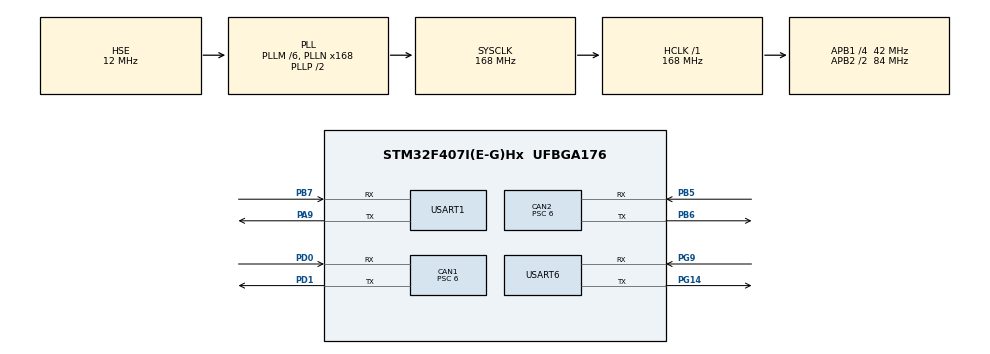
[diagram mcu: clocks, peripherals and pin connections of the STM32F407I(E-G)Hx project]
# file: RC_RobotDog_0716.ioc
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CAN1.BS1=CAN_BS1_3TQ
CAN1.BS2=CAN_BS2_3TQ
CAN1.CalculateBaudRate=1000000
CAN1.CalculateTimeBit=1000
CAN1.CalculateTimeQuantum=142.85714285714286
CAN1.NART=ENABLE
CAN1.Prescaler=6
CAN2.BS1=CAN_BS1_3TQ
CAN2.BS2=CAN_BS2_3TQ
CAN2.CalculateBaudRate=1000000
CAN2.CalculateTimeBit=1000
CAN2.CalculateTimeQuantum=142.85714285714286
CAN2.Prescaler=6
Dma.Request0=USART6_RX
Dma.Request1=USART1_RX
Dma.USART1_RX.1.Direction=DMA_PERIPH_TO_MEMORY
Dma.USART1_RX.1.FIFOMode=DMA_FIFOMODE_DISABLE
Dma.USART1_RX.1.Instance=DMA2_Stream2
Dma.USART1_RX.1.MemDataAlignment=DMA_MDATAALIGN_BYTE
Dma.USART1_RX.1.MemInc=DMA_MINC_ENABLE
Dma.USART1_RX.1.Mode=DMA_NORMAL
Dma.USART1_RX.1.PeriphDataAlignment=DMA_PDATAALIGN_BYTE
Dma.USART1_RX.1.PeriphInc=DMA_PINC_DISABLE
Dma.USART1_RX.1.Priority=DMA_PRIORITY_LOW
Dma.USART6_RX.0.Direction=DMA_PERIPH_TO_MEMORY
Dma.USART6_RX.0.FIFOMode=DMA_FIFOMODE_ENABLE
Dma.USART6_RX.0.FIFOThreshold=DMA_FIFO_THRESHOLD_FULL
Dma.USART6_RX.0.Instance=DMA2_Stream1
Dma.USART6_RX.0.MemBurst=DMA_MBURST_SINGLE
Dma.USART6_RX.0.MemDataAlignment=DMA_MDATAALIGN_BYTE
Dma.USART6_RX.0.MemInc=DMA_MINC_ENABLE
Dma.USART6_RX.0.Mode=DMA_NORMAL
Dma.USART6_RX.0.PeriphBurst=DMA_PBURST_SINGLE
Dma.USART6_RX.0.PeriphDataAlignment=DMA_PDATAALIGN_BYTE
Dma.USART6_RX.0.PeriphInc=DMA_PINC_DISABLE
Dma.USART6_RX.0.Priority=DMA_PRIORITY_HIGH
Mcu.Family=STM32F4
Mcu.Name=STM32F407I(E-G)Hx
Mcu.Package=UFBGA176
NVIC.CAN1_RX0_IRQn=true\:2\:0\:true\:false\:true\:true\:true\:true
NVIC.CAN1_RX1_IRQn=true\:2\:0\:true\:false\:true\:true\:true\:true
NVIC.CAN1_SCE_IRQn=true\:2\:0\:true\:false\:true\:true\:true\:true
NVIC.CAN1_TX_IRQn=true\:2\:0\:true\:false\:true\:true\:true\:true
NVIC.CAN2_RX0_IRQn=true\:2\:0\:true\:false\:true\:true\:true\:true
NVIC.CAN2_RX1_IRQn=true\:2\:0\:true\:false\:true\:true\:true\:true
NVIC.CAN2_SCE_IRQn=true\:2\:0\:true\:false\:true\:true\:true\:true
NVIC.CAN2_TX_IRQn=true\:2\:0\:true\:false\:true\:true\:true\:true
NVIC.DMA2_Stream1_IRQn=true\:0\:0\:true\:false\:true\:false\:true\:true
NVIC.DMA2_Stream2_IRQn=true\:0\:0\:true\:false\:true\:false\:true\:true
NVIC.PriorityGroup=NVIC_PRIORITYGROUP_4
NVIC.TIM1_BRK_TIM9_IRQn=true\:1\:0\:true\:false\:true\:true\:true\:true
NVIC.TIM1_CC_IRQn=true\:1\:0\:true\:false\:true\:true\:true\:true
NVIC.TIM1_TRG_COM_TIM11_IRQn=true\:1\:0\:true\:false\:true\:true\:true\:true
NVIC.TIM1_UP_TIM10_IRQn=true\:1\:0\:true\:false\:true\:true\:true\:true
NVIC.TIM2_IRQn=true\:1\:0\:true\:false\:true\:true\:true\:true
NVIC.TIM6_DAC_IRQn=true\:1\:0\:true\:false\:true\:true\:true\:true
NVIC.USART1_IRQn=true\:0\:0\:true\:false\:true\:true\:true\:true
NVIC.USART6_IRQn=true\:0\:0\:true\:false\:true\:true\:true\:true
PA13.Mode=Serial_Wire
PA13.Signal=SYS_JTMS-SWDIO
PA14.Mode=Serial_Wire
PA14.Signal=SYS_JTCK-SWCLK
PA9.Mode=Asynchronous
PA9.Signal=USART1_TX
PB5.Mode=CAN_Activate
PB5.Signal=CAN2_RX
PB6.Mode=CAN_Activate
PB6.Signal=CAN2_TX
PB7.Mode=Asynchronous
PB7.Signal=USART1_RX
PD0.Mode=CAN_Activate
PD0.Signal=CAN1_RX
PD1.Mode=CAN_Activate
PD1.Signal=CAN1_TX
PG14.Mode=Asynchronous
PG14.Signal=USART6_TX
PG9.Mode=Asynchronous
PG9.Signal=USART6_RX
PH0-OSC_IN.Mode=HSE-External-Oscillator
PH0-OSC_IN.Signal=RCC_OSC_IN
PH1-OSC_OUT.Mode=HSE-External-Oscillator
PH1-OSC_OUT.Signal=RCC_OSC_OUT
ProjectManager.HeapSize=0x200
ProjectManager.StackSize=0x400
ProjectManager.TargetToolchain=CMake
RCC.48MHZClocksFreq_Value=84000000
RCC.AHBFreq_Value=168000000
RCC.APB1CLKDivider=RCC_HCLK_DIV4
RCC.APB1Freq_Value=42000000
RCC.APB1TimFreq_Value=84000000
RCC.APB2CLKDivider=RCC_HCLK_DIV2
RCC.APB2Freq_Value=84000000
RCC.APB2TimFreq_Value=168000000
RCC.CortexFreq_Value=168000000
RCC.HCLKFreq_Value=168000000
RCC.HSE_VALUE=12000000
RCC.HSI_VALUE=16000000
RCC.LSE_VALUE=32768
RCC.PLLM=6
RCC.PLLN=168
RCC.PLLSourceVirtual=RCC_PLLSOURCE_HSE
RCC.SYSCLKFreq_VALUE=168000000
RCC.SYSCLKSource=RCC_SYSCLKSOURCE_PLLCLK
RCC.VCOOutputFreq_Value=336000000
TIM1.Period=9
TIM1.Prescaler=8399
TIM2.Period=9
TIM2.Prescaler=8399
TIM6.Period=9
TIM6.Prescaler=8399
USART1.VirtualMode=VM_ASYNC
USART6.VirtualMode=VM_ASYNC
VP_TIM1_VS_ClockSourceINT.Mode=Internal
VP_TIM2_VS_ClockSourceINT.Mode=Internal
VP_TIM6_VS_ClockSourceINT.Mode=Enable_Timer
board=custom

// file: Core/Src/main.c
/* USER CODE BEGIN Header */
/**
  ******************************************************************************
  * @file           : main.c
  * @brief          : Main program body
  ******************************************************************************
  * @attention
  *
  * Copyright (c) 2026 STMicroelectronics.
  * All rights reserved.
  *
  * This software is licensed under terms that can be found in the LICENSE file
  * in the root directory of this software component.
  * If no LICENSE file comes with this software, it is provided AS-IS.
  *
  ******************************************************************************
  */
/* USER CODE END Header */
#include "main.h"
#include "can.h"
#include "dma.h"
#include "tim.h"
#include "usart.h"
#include "gpio.h"

/* USER CODE BEGIN Includes */
#include "callback_task.h"

/* USER CODE END Includes */

void SystemClock_Config(void);

/* USER CODE BEGIN 0 */
int flag4;
/* USER CODE END 0 */

int main(void)
{

  /* MCU Configuration--------------------------------------------------------*/

  /* Reset of all peripherals, Initializes the Flash interface and the Systick. */
  HAL_Init();

  /* Configure the system clock */
  SystemClock_Config();

  /* Initialize all configured peripherals */
  MX_GPIO_Init();
  MX_DMA_Init();
  MX_CAN1_Init();
  MX_CAN2_Init();
  MX_TIM1_Init();
  MX_TIM2_Init();
  MX_TIM6_Init();
  MX_USART6_UART_Init();
  MX_USART1_UART_Init();
  /* USER CODE BEGIN 2 */

  HAL_Delay(2000);

  Robot_Init();

  /* USER CODE END 2 */

  /* Infinite loop */
  while (1)
  {

  }
}

void SystemClock_Config(void)
{
  RCC_OscInitTypeDef RCC_OscInitStruct = {0};
  RCC_ClkInitTypeDef RCC_ClkInitStruct = {0};

  /** Configure the main internal regulator output voltage
  */
  __HAL_RCC_PWR_CLK_ENABLE();
  __HAL_PWR_VOLTAGESCALING_CONFIG(PWR_REGULATOR_VOLTAGE_SCALE1);

  /** Initializes the RCC Oscillators according to the specified parameters
  * in the RCC_OscInitTypeDef structure.
  */
  RCC_OscInitStruct.OscillatorType = RCC_OSCILLATORTYPE_HSE;
  RCC_OscInitStruct.HSEState = RCC_HSE_ON;
  RCC_OscInitStruct.PLL.PLLState = RCC_PLL_ON;
  RCC_OscInitStruct.PLL.PLLSource = RCC_PLLSOURCE_HSE;
  RCC_OscInitStruct.PLL.PLLM = 6;
  RCC_OscInitStruct.PLL.PLLN = 168;
  RCC_OscInitStruct.PLL.PLLP = RCC_PLLP_DIV2;
  RCC_OscInitStruct.PLL.PLLQ = 4;
  if (HAL_RCC_OscConfig(&RCC_OscInitStruct) != HAL_OK)
  {
    Error_Handler();
  }

  /** Initializes the CPU, AHB and APB buses clocks
  */
  RCC_ClkInitStruct.ClockType = RCC_CLOCKTYPE_HCLK|RCC_CLOCKTYPE_SYSCLK
                              |RCC_CLOCKTYPE_PCLK1|RCC_CLOCKTYPE_PCLK2;
  RCC_ClkInitStruct.SYSCLKSource = RCC_SYSCLKSOURCE_PLLCLK;
  RCC_ClkInitStruct.AHBCLKDivider = RCC_SYSCLK_DIV1;
  RCC_ClkInitStruct.APB1CLKDivider = RCC_HCLK_DIV4;
  RCC_ClkInitStruct.APB2CLKDivider = RCC_HCLK_DIV2;

  if (HAL_RCC_ClockConfig(&RCC_ClkInitStruct, FLASH_LATENCY_5) != HAL_OK)
  {
    Error_Handler();
  }
}

void Error_Handler(void)
{
  __disable_irq();
  while (1)
  {
  }
}
